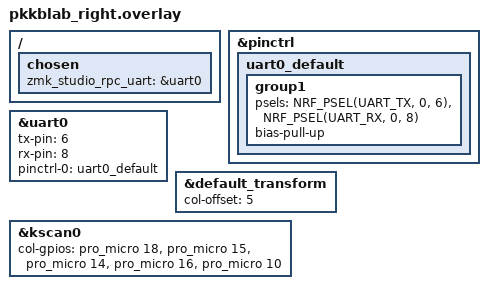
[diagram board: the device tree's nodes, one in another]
/ {
	chosen {
		zmk_studio_rpc_uart = &uart0;
	};
};

&pinctrl {
	uart0_default: uart0_default {
		group1 {
			psels = <NRF_PSEL(UART_TX, 0, 6)>,
					<NRF_PSEL(UART_RX, 0, 8)>;
			bias-pull-up;
		};
	};
};

&uart0 {
	status = "okay";
	tx-pin = <6>;
	rx-pin = <8>;
	pinctrl-0 = <&uart0_default>;
	pinctrl-names = "default";
};

#include "pkkblab.dtsi"

&default_transform {
    col-offset = <5>;
};

&kscan0 {
    col-gpios
        = <&pro_micro 18 GPIO_ACTIVE_HIGH>
        , <&pro_micro 15 GPIO_ACTIVE_HIGH>
        , <&pro_micro 14 GPIO_ACTIVE_HIGH>
        , <&pro_micro 16 GPIO_ACTIVE_HIGH>
        , <&pro_micro 10 GPIO_ACTIVE_HIGH>
        ;
};
